# cslr_gpio register map
Vendor: Texas Instruments
Peripheral module from a debugger description file (folder TCI6484_C6457).
Registers are 32-bit, access not given, reset 0x0 unless marked. A register's access mark holds for its fields unless they carry their own. Offsets are as the file gives them; lines under a group give offsets from that group; [hi:lo] are bit positions; {n}, {i} and the like mark numbered series; 'fields as' and 'values as' point back to an identical list; <NAME> marks a mode.

## GPIO — General Purpose Input Output
0x08 BINTEN — GPIO Interrupt Per-Bank Enable Register
  [0] EN rw — Per-bank interrupt enable
    0=DISABLE (Disables interrupt); 1=ENABLE (Enables interrupt)
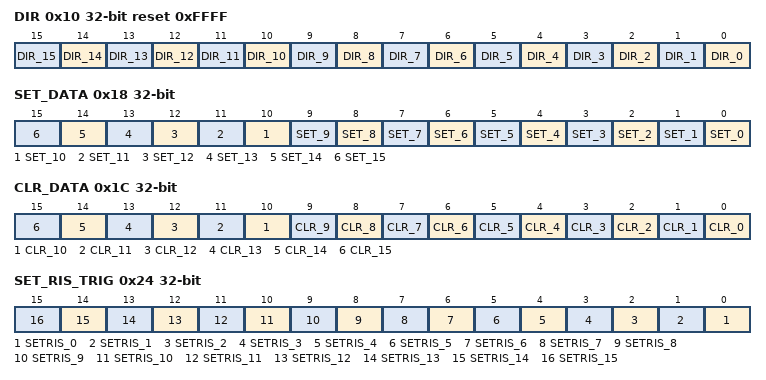
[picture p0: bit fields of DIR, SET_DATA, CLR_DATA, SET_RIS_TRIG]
0x10 DIR reset 0xFFFF — GPIO Direction Register
  [all] fields
    0=OUT (Output); 1=IN (Input)
  [n] DIR_{n} rw (n=0..15) — Direction of GPIO bank bit 0...15. It selects the direction for 16 GPIO signals
0x14 OUT_DATA — GPIO Output Data Register
  [15] OUT_15 rw — Output drive state of GPIO bank bit 0...15 Bits 0-15 form 16 GPIO signals of the bank Does not affect operation when it is configured as input. Reading it returns the output drive state
0x18 SET_DATA — GPIO Set Data Register
  [14] OUT_14 rw — Output drive state of GPIO bank bit 0...15 Bits 0-15 form 16 GPIO signals of the bank Does not affect operation when it is configured as input. Reading it returns the output drive state
0x18 SET_DATA — GPIO Set Data Register
  [13] OUT_13 rw — Output drive state of GPIO bank bit 0...15 Bits 0-15 form 16 GPIO signals of the bank Does not affect operation when it is configured as input. Reading it returns the output drive state
0x18 SET_DATA — GPIO Set Data Register
  [12] OUT_12 rw — Output drive state of GPIO bank bit 0...15 Bits 0-15 form 16 GPIO signals of the bank Does not affect operation when it is configured as input. Reading it returns the output drive state
0x18 SET_DATA — GPIO Set Data Register
  [11] OUT_11 rw — Output drive state of GPIO bank bit 0...15 Bits 0-15 form 16 GPIO signals of the bank Does not affect operation when it is configured as input. Reading it returns the output drive state
0x18 SET_DATA — GPIO Set Data Register
  [10] OUT_10 rw — Output drive state of GPIO bank bit 0...15 Bits 0-15 form 16 GPIO signals of the bank Does not affect operation when it is configured as input. Reading it returns the output drive state
0x18 SET_DATA — GPIO Set Data Register
  [9] OUT_9 rw — Output drive state of GPIO bank bit 0...15 Bits 0-15 form 16 GPIO signals of the bank Does not affect operation when it is configured as input. Reading it returns the output drive state
0x18 SET_DATA — GPIO Set Data Register
  [8] OUT_8 rw — Output drive state of GPIO bank bit 0...15 Bits 0-15 form 16 GPIO signals of the bank Does not affect operation when it is configured as input. Reading it returns the output drive state
0x18 SET_DATA — GPIO Set Data Register
  [7] OUT_7 rw — Output drive state of GPIO bank bit 0...15 Bits 0-15 form 16 GPIO signals of the bank Does not affect operation when it is configured as input. Reading it returns the output drive state
0x18 SET_DATA — GPIO Set Data Register
  [6] OUT_6 rw — Output drive state of GPIO bank bit 0...15 Bits 0-15 form 16 GPIO signals of the bank Does not affect operation when it is configured as input. Reading it returns the output drive state
0x18 SET_DATA — GPIO Set Data Register
  [5] OUT_5 rw — Output drive state of GPIO bank bit 0...15 Bits 0-15 form 16 GPIO signals of the bank Does not affect operation when it is configured as input. Reading it returns the output drive state
0x18 SET_DATA — GPIO Set Data Register
  [4] OUT_4 rw — Output drive state of GPIO bank bit 0...15 Bits 0-15 form 16 GPIO signals of the bank Does not affect operation when it is configured as input. Reading it returns the output drive state
0x18 SET_DATA — GPIO Set Data Register
  [3] OUT_3 rw — Output drive state of GPIO bank bit 0...15 Bits 0-15 form 16 GPIO signals of the bank Does not affect operation when it is configured as input. Reading it returns the output drive state
0x18 SET_DATA — GPIO Set Data Register
  [2] OUT_2 rw — Output drive state of GPIO bank bit 0...15 Bits 0-15 form 16 GPIO signals of the bank Does not affect operation when it is configured as input. Reading it returns the output drive state
0x18 SET_DATA — GPIO Set Data Register
  [1] OUT_1 rw — Output drive state of GPIO bank bit 0...15 Bits 0-15 form 16 GPIO signals of the bank Does not affect operation when it is configured as input. Reading it returns the output drive state
0x18 SET_DATA — GPIO Set Data Register
  [0] OUT_0 rw — Output drive state of GPIO bank bit 0...15 Bits 0-15 form 16 GPIO signals of the bank Does not affect operation when it is configured as input. Reading it returns the output drive state
0x18 SET_DATA — GPIO Set Data Register
  [all] fields
    1=SET (Set output to 1)
  [n] SET_{n} rw (n=0..15) — Set output drive state of GPIO bank 0...15 Bits 0-15 form 16 GPIO signals of the bank Writing 1 sets the output drive state of corresponding GPIO signal. Reading it returns the output drive state
0x1C CLR_DATA — GPIO Clear Data Register
  [all] fields
    1=CLR (Clear output to 0)
  [n] CLR_{n} rw (n=0..15) — Clear output drive state of GPIO bank bit 0...15 Bits 0-15 form 16 GPIO signals of the bank Writing 1 clears the output drive state of corresponding GPIO. Reading it returns the output drive state
0x20 IN_DATA (reset mask 0xFFFF0000) — GPIO Input Data Register
  [15] IN_15 ro — Status of GPIO bank bit 0...15 Bits 0-15 form 16 GPIO signals of the bank
0x24 SET_RIS_TRIG (reset mask 0xFFFF0000) — GPIO Set Rising Edge Interrupt Register
  [14] IN_14 ro — Status of GPIO bank bit 0...15 Bits 0-15 form 16 GPIO signals of the bank
0x24 SET_RIS_TRIG (reset mask 0xFFFF0000) — GPIO Set Rising Edge Interrupt Register
  [13] IN_13 ro — Status of GPIO bank bit 0...15 Bits 0-15 form 16 GPIO signals of the bank
0x24 SET_RIS_TRIG (reset mask 0xFFFF0000) — GPIO Set Rising Edge Interrupt Register
  [12] IN_12 ro — Status of GPIO bank bit 0...15 Bits 0-15 form 16 GPIO signals of the bank
0x24 SET_RIS_TRIG (reset mask 0xFFFF0000) — GPIO Set Rising Edge Interrupt Register
  [11] IN_11 ro — Status of GPIO bank bit 0...15 Bits 0-15 form 16 GPIO signals of the bank
0x24 SET_RIS_TRIG (reset mask 0xFFFF0000) — GPIO Set Rising Edge Interrupt Register
  [10] IN_10 ro — Status of GPIO bank bit 0...15 Bits 0-15 form 16 GPIO signals of the bank
0x24 SET_RIS_TRIG (reset mask 0xFFFF0000) — GPIO Set Rising Edge Interrupt Register
  [9] IN_9 ro — Status of GPIO bank bit 0...15 Bits 0-15 form 16 GPIO signals of the bank
0x24 SET_RIS_TRIG (reset mask 0xFFFF0000) — GPIO Set Rising Edge Interrupt Register
  [8] IN_8 ro — Status of GPIO bank bit 0...15 Bits 0-15 form 16 GPIO signals of the bank
0x24 SET_RIS_TRIG (reset mask 0xFFFF0000) — GPIO Set Rising Edge Interrupt Register
  [7] IN_7 ro — Status of GPIO bank bit 0...15 Bits 0-15 form 16 GPIO signals of the bank
0x24 SET_RIS_TRIG (reset mask 0xFFFF0000) — GPIO Set Rising Edge Interrupt Register
  [6] IN_6 ro — Status of GPIO bank bit 0...15 Bits 0-15 form 16 GPIO signals of the bank
0x24 SET_RIS_TRIG (reset mask 0xFFFF0000) — GPIO Set Rising Edge Interrupt Register
  [5] IN_5 ro — Status of GPIO bank bit 0...15 Bits 0-15 form 16 GPIO signals of the bank
0x24 SET_RIS_TRIG (reset mask 0xFFFF0000) — GPIO Set Rising Edge Interrupt Register
  [4] IN_4 ro — Status of GPIO bank bit 0...15 Bits 0-15 form 16 GPIO signals of the bank
0x24 SET_RIS_TRIG (reset mask 0xFFFF0000) — GPIO Set Rising Edge Interrupt Register
  [3] IN_3 ro — Status of GPIO bank bit 0...15 Bits 0-15 form 16 GPIO signals of the bank
0x24 SET_RIS_TRIG (reset mask 0xFFFF0000) — GPIO Set Rising Edge Interrupt Register
  [2] IN_2 ro — Status of GPIO bank bit 0...15 Bits 0-15 form 16 GPIO signals of the bank
0x24 SET_RIS_TRIG (reset mask 0xFFFF0000) — GPIO Set Rising Edge Interrupt Register
  [1] IN_1 ro — Status of GPIO bank bit 0...15 Bits 0-15 form 16 GPIO signals of the bank
0x24 SET_RIS_TRIG (reset mask 0xFFFF0000) — GPIO Set Rising Edge Interrupt Register
  [0] IN_0 ro — Status of GPIO bank bit 0...15 Bits 0-15 form 16 GPIO signals of the bank
0x24 SET_RIS_TRIG — GPIO Set Rising Edge Interrupt Register
  [all] fields
    1=ENABLE
  [n] SETRIS_{n} rw (n=0..15) — Enable Rising edge interrupt detection for GPIO bank bit 0...15 Bits 0-15 form 16 GPIO signals of the bank Reading returns state of RIS_TRG
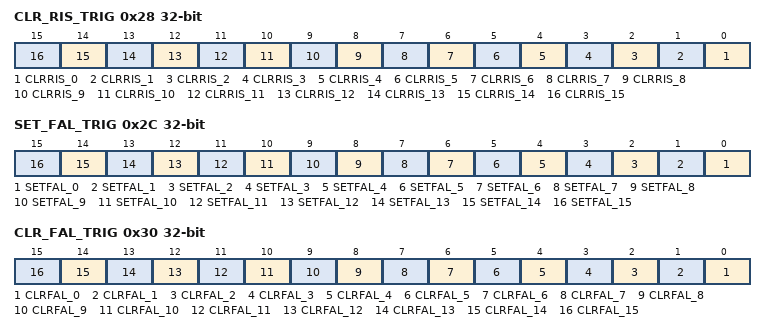
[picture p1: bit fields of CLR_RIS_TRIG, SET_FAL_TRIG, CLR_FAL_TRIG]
0x28 CLR_RIS_TRIG — GPIO Clear Rising Edge Interrupt Register
  [all] fields
    0=DISABLE
  [n] CLRRIS_{n} rw (n=0..15) — Disable Rising edge interrupt detection for GPIO bank bit 0...15 Bits 0-15 form 16 GPIO signals of the bank Reading returns complement state of RIS_TRG
0x2C SET_FAL_TRIG — GPIO Set Falling Edge Interrupt Register
  [all] fields
    1=ENABLE
  [n] SETFAL_{n} rw (n=0..15) — Enable Falling edge interrupt detection for GPIO bank bit 0...15 Bits 0-15 form 16 GPIO signals of the bank Reading returns state of FAL_TRG
0x30 CLR_FAL_TRIG — GPIO Clear Falling Edge Interrupt Register
  [all] fields
    0=DISABLE
  [n] CLRFAL_{n} rw (n=0..15) — Disable Falling edge interrupt detection for GPIO bank bit 0...15 Bits 0-15 form 16 GPIO signals of the bank Reading returns complement state of FAL_TRG
